# STM32WB15_CM4 register map
File version: 1.5
CPU: CM4 r0p1, little endian, MPU, FPU, 4 interrupt priority bits
Registers are 32-bit, read-write, reset 0x0 unless marked. A register's access mark holds for its fields unless they carry their own. Offsets are from the block's base; [hi:lo] are bit positions.

## COMP — Comparator instance 1
Base 0x40010200
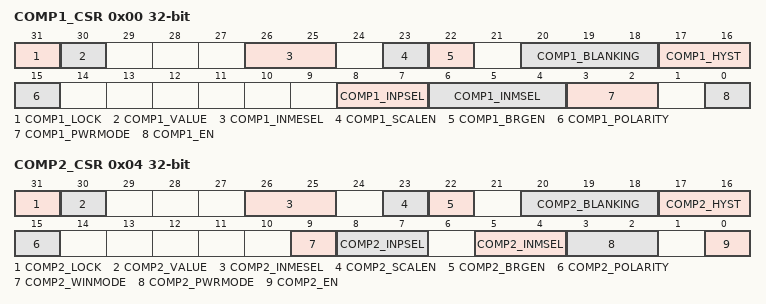
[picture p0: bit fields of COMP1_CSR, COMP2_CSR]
0x00 COMP1_CSR access per field — Comparator control and status register
  [31] COMP1_LOCK rw — Comparator lock
  [30] COMP1_VALUE ro — Comparator output level
  [26:25] COMP1_INMESEL rw — Comparator input minus extended selection
  [23] COMP1_SCALEN rw — Comparator scaler bridge enable
  [22] COMP1_BRGEN rw — Comparator voltage scaler enable
  [20:18] COMP1_BLANKING rw — Comparator blanking source
  [17:16] COMP1_HYST rw — Comparator hysteresis
  [15] COMP1_POLARITY rw — Comparator output polarity
  [8:7] COMP1_INPSEL rw — Comparator input plus selection
  [6:4] COMP1_INMSEL rw — Comparator input minus selection
  [3:2] COMP1_PWRMODE rw — Comparator power mode
  [0] COMP1_EN rw — Comparator enable
0x04 COMP2_CSR access per field — Comparator 2 control and status register
  [31] COMP2_LOCK rw — CSR register lock bit
  [30] COMP2_VALUE ro — Comparator 2 output status bit
  [26:25] COMP2_INMESEL rw — comparator 2 input minus extended selection bits.
  [23] COMP2_SCALEN rw — Voltage scaler enable bit
  [22] COMP2_BRGEN rw — Scaler bridge enable
  [20:18] COMP2_BLANKING rw — Comparator 2 blanking source selection bits
  [17:16] COMP2_HYST rw — Comparator 2 hysteresis selection bits
  [15] COMP2_POLARITY rw — Comparator 2 polarity selection bit
  [9] COMP2_WINMODE rw — Windows mode selection bit
  [8:7] COMP2_INPSEL rw — Comparator 1 input plus selection bit
  [5:4] COMP2_INMSEL rw — Comparator 2 input minus selection bits
  [3:2] COMP2_PWRMODE rw — Power Mode of the comparator 2
  [0] COMP2_EN rw — Comparator 2 enable bit

## CRC — Cyclic redundancy check calculation unit
Base 0x40023000
0x00 DR reset 0xFFFFFFFF — Data register
  [31:0] DR — Data register bits
0x04 IDR — Independent data register
  [31:0] IDR — General-purpose 32-bit data register bits
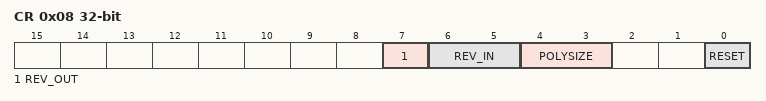
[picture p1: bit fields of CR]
0x08 CR — Control register
  [7] REV_OUT — Reverse output data
  [6:5] REV_IN — Reverse input data
  [4:3] POLYSIZE — Polynomial size
  [0] RESET — RESET bit
0x10 INIT reset 0xFFFFFFFF — Initial CRC value
  [31:0] CRC_INIT — Programmable initial CRC value
0x14 POL reset 0x4C11DB7 — polynomial
  [31:0] POL — Programmable polynomial

## DBGMCU — Debug support
Base 0xE0042000
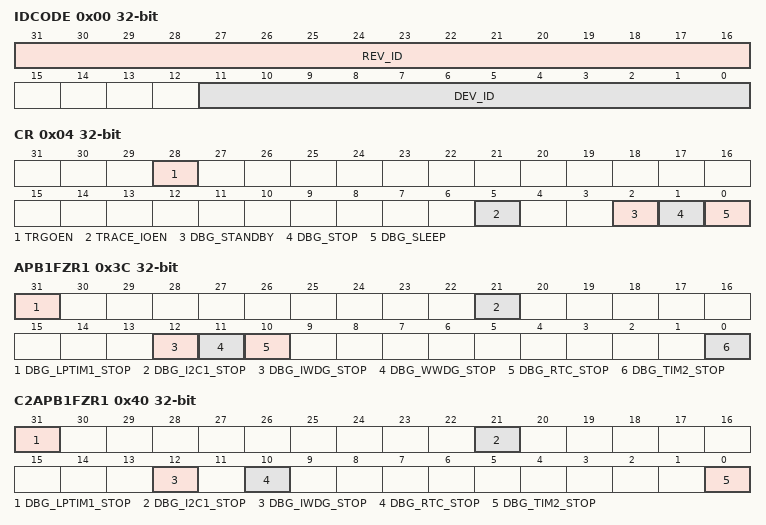
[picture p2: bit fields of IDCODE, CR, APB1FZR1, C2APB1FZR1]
0x00 IDCODE ro — MCU Device ID Code Register
  [31:16] REV_ID — Revision Identifier
  [11:0] DEV_ID — Device Identifier
0x04 CR — Debug MCU Configuration Register
  [28] TRGOEN — External trigger output enable
  [5] TRACE_IOEN — Trace port and clock enable
  [2] DBG_STANDBY — Debug Standby Mode
  [1] DBG_STOP — Debug Stop Mode
  [0] DBG_SLEEP — Debug Sleep Mode
0x3C APB1FZR1 — APB1 Low Freeze Register CPU1
  [31] DBG_LPTIM1_STOP — Debug LPTIM1 stopped when Core is halted
  [21] DBG_I2C1_STOP — Debug I2C1 SMBUS timeout stopped when Core is halted
  [12] DBG_IWDG_STOP — IWDG counter stopped when core is halted
  [11] DBG_WWDG_STOP — WWDG counter stopped when core is halted
  [10] DBG_RTC_STOP — RTC counter stopped when core is halted
  [0] DBG_TIM2_STOP — Debug Timer 2 stopped when Core is halted
0x40 C2APB1FZR1 — APB1 Low Freeze Register CPU2
  [31] DBG_LPTIM1_STOP — LPTIM1 counter stopped when core is halted
  [21] DBG_I2C1_STOP — I2C1 SMBUS timeout stopped when core is halted
  [12] DBG_IWDG_STOP — IWDG stopped when core is halted
  [10] DBG_RTC_STOP — RTC counter stopped when core is halted
  [0] DBG_TIM2_STOP — LPTIM2 counter stopped when core is halted
0x44 APB1FZR2 — APB1 High Freeze Register CPU1
  [5] DBG_LPTIM2_STOP — LPTIM2 counter stopped when core is halted
0x48 C2APB1FZR2 — APB1 High Freeze Register CPU2
  [5] DBG_LPTIM2_STOP — LPTIM2 counter stopped when core is halted
0x4C APB2FZR — APB2 Freeze Register CPU1
  [11] DBG_TIM1_STOP — TIM1 counter stopped when core is halted
0x50 C2APB2FZR (alternate view of C2APB1FZR2) — APB2 Freeze Register CPU2
  [11] DBG_TIM1_STOP — TIM1 counter stopped when core is halted

## Notices in the file
Copyright (c) 2024 STMicroelectronics.
SPDX-License-Identifier: Apache-2.0
Licensed under the Apache License, Version 2.0 (the "License");
you may not use this file except in compliance with the License.
You may obtain a copy of the License at
http://www.apache.org/licenses/LICENSE-2.0
Unless required by applicable law or agreed to in writing, software
distributed under the License is distributed on an "AS IS" BASIS,
WITHOUT WARRANTIES OR CONDITIONS OF ANY KIND, either express or implied.
See the License for the specific language governing permissions and
limitations under the License.
